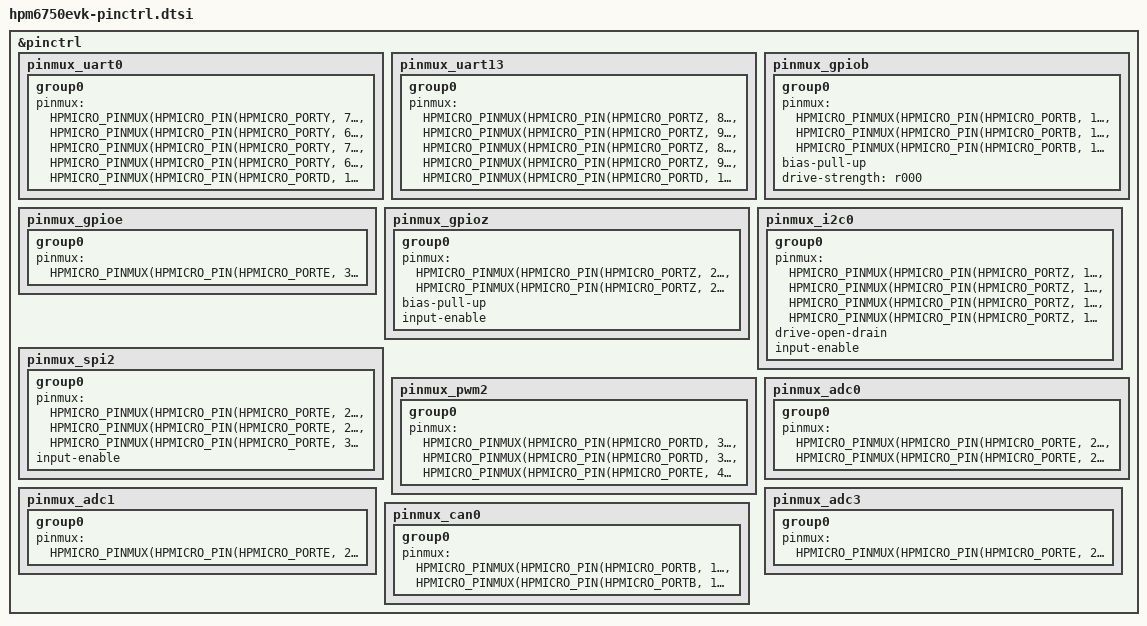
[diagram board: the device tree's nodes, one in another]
/*
 * Copyright 2022 hpmicro
 * SPDX-License-Identifier: Apache-2.0
 */
 
#include "dt-bindings/pinctrl/hpmicro-pinctrl-common.h"

&pinctrl {
	pinmux_uart0: pinmux_uart0 {
		group0 {
			pinmux = <HPMICRO_PINMUX(HPMICRO_PIN(HPMICRO_PORTY, 7), IOC_TYPE_IOC, 0, 2)>,
					 <HPMICRO_PINMUX(HPMICRO_PIN(HPMICRO_PORTY, 6), IOC_TYPE_IOC, 0, 2)>,
					 <HPMICRO_PINMUX(HPMICRO_PIN(HPMICRO_PORTY, 7), IOC_TYPE_PIOC, 0, 3)>,
					 <HPMICRO_PINMUX(HPMICRO_PIN(HPMICRO_PORTY, 6), IOC_TYPE_PIOC, 0, 3)>,
					 <HPMICRO_PINMUX(HPMICRO_PIN(HPMICRO_PORTD, 19), IOC_TYPE_IOC, 0, 16)>;
		};
	};
	pinmux_uart13: pinmux_uart13 {
		group0 {
			pinmux = <HPMICRO_PINMUX(HPMICRO_PIN(HPMICRO_PORTZ, 8), IOC_TYPE_IOC, 0, 2)>,
					 <HPMICRO_PINMUX(HPMICRO_PIN(HPMICRO_PORTZ, 9), IOC_TYPE_IOC, 0, 2)>,
					 <HPMICRO_PINMUX(HPMICRO_PIN(HPMICRO_PORTZ, 8), IOC_TYPE_BIOC, 0, 3)>,
					 <HPMICRO_PINMUX(HPMICRO_PIN(HPMICRO_PORTZ, 9), IOC_TYPE_BIOC, 0, 3)>,
					 <HPMICRO_PINMUX(HPMICRO_PIN(HPMICRO_PORTD, 19), IOC_TYPE_IOC, 0, 16)>;
		};
	};
	pinmux_gpiob: pinmux_gpiob {
		group0 {
			pinmux = <HPMICRO_PINMUX(HPMICRO_PIN(HPMICRO_PORTB, 11), IOC_TYPE_IOC, 0, 0)>,
					 <HPMICRO_PINMUX(HPMICRO_PIN(HPMICRO_PORTB, 12), IOC_TYPE_IOC, 0, 0)>,
					 <HPMICRO_PINMUX(HPMICRO_PIN(HPMICRO_PORTB, 13), IOC_TYPE_IOC, 0, 0)>;
			bias-pull-up;
      		drive-strength = "r000";
					 
		};
	};

	pinmux_gpioe: pinmux_gpioe {
		group0 {
			pinmux = <HPMICRO_PINMUX(HPMICRO_PIN(HPMICRO_PORTE, 31), IOC_TYPE_IOC, 0, 0)>;
		};
	};

	pinmux_gpioz: pinmux_gpioz {
		group0 {
			pinmux = <HPMICRO_PINMUX(HPMICRO_PIN(HPMICRO_PORTZ, 2), IOC_TYPE_IOC, 0, 0)>,
					 <HPMICRO_PINMUX(HPMICRO_PIN(HPMICRO_PORTZ, 2), IOC_TYPE_BIOC, 0, 3)>;
			bias-pull-up;
			input-enable;
		};
	};

	pinmux_i2c0: pinmux_i2c0 {
		group0 {
			pinmux = <HPMICRO_PINMUX(HPMICRO_PIN(HPMICRO_PORTZ, 10), IOC_TYPE_IOC, 0, 4)>,
					 <HPMICRO_PINMUX(HPMICRO_PIN(HPMICRO_PORTZ, 11), IOC_TYPE_IOC, 0, 4)>,
					 <HPMICRO_PINMUX(HPMICRO_PIN(HPMICRO_PORTZ, 10), IOC_TYPE_BIOC, 0, 3)>,
					 <HPMICRO_PINMUX(HPMICRO_PIN(HPMICRO_PORTZ, 11), IOC_TYPE_BIOC, 0, 3)>;
			drive-open-drain;
			input-enable;
		};
	};

	pinmux_spi2: pinmux_spi2 {
		group0 {
			pinmux = <HPMICRO_PINMUX(HPMICRO_PIN(HPMICRO_PORTE, 27), IOC_TYPE_IOC, 0, 5)>,
					 <HPMICRO_PINMUX(HPMICRO_PIN(HPMICRO_PORTE, 28), IOC_TYPE_IOC, 0, 5)>,
					 <HPMICRO_PINMUX(HPMICRO_PIN(HPMICRO_PORTE, 30), IOC_TYPE_IOC, 0, 5)>;
			input-enable;
		};
	};

	pinmux_pwm2: pinmux_pwm2 {
		group0 {
			pinmux = <HPMICRO_PINMUX(HPMICRO_PIN(HPMICRO_PORTD, 31), IOC_TYPE_IOC, 0, 16)>,
					 <HPMICRO_PINMUX(HPMICRO_PIN(HPMICRO_PORTD, 30), IOC_TYPE_IOC, 0, 16)>,
					 <HPMICRO_PINMUX(HPMICRO_PIN(HPMICRO_PORTE, 4), IOC_TYPE_IOC, 0, 16)>;
		};
	};

	pinmux_adc0: pinmux_adc0 {
		group0 {
			pinmux = <HPMICRO_PINMUX(HPMICRO_PIN(HPMICRO_PORTE, 24), IOC_TYPE_IOC, 1, 0)>,
					 <HPMICRO_PINMUX(HPMICRO_PIN(HPMICRO_PORTE, 25), IOC_TYPE_IOC, 1, 0)>;
		};
	};

	pinmux_adc1: pinmux_adc1 {
		group0 {
			pinmux = <HPMICRO_PINMUX(HPMICRO_PIN(HPMICRO_PORTE, 21), IOC_TYPE_IOC, 1, 0)>;
		};
	};

	pinmux_adc3: pinmux_adc3 {
		group0 {
			pinmux = <HPMICRO_PINMUX(HPMICRO_PIN(HPMICRO_PORTE, 29), IOC_TYPE_IOC, 1, 0)>;
		};
	};

    pinmux_can0: pinmux_can0 {
        group0 {
            pinmux = <HPMICRO_PINMUX(HPMICRO_PIN(HPMICRO_PORTB, 15), IOC_TYPE_IOC, 0, 7)>,
                     <HPMICRO_PINMUX(HPMICRO_PIN(HPMICRO_PORTB, 17), IOC_TYPE_IOC, 0, 7)>;
        };
    };
};
